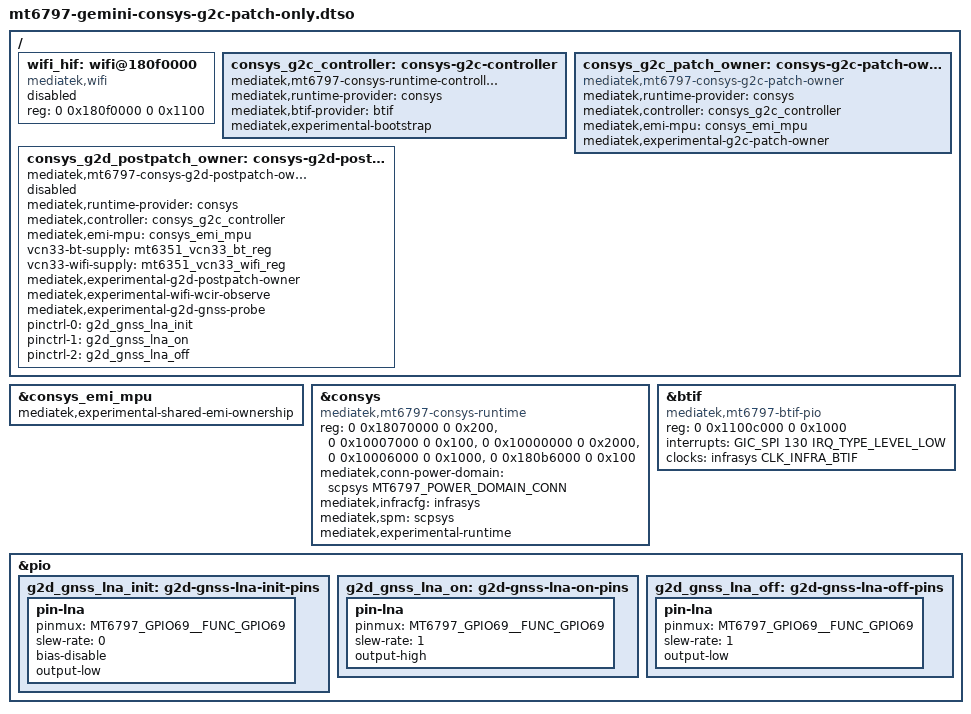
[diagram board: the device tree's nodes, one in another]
// SPDX-License-Identifier: GPL-2.0-only
/*
 * One MT6797 G2c wire-cycle: the G2b chronology plus the hash-pinned WMT
 * patch manifest.  It does not issue WMT function control, register HCI or
 * Wi-Fi, expose a user endpoint, associate, or transmit a host-originated
 * radio frame.  Like G2b, it fences BTIF and restores reset-held state before
 * returning.  Firmware-internal reset effects remain unknown.
 */

/dts-v1/;
/plugin/;

#include <dt-bindings/clock/mt6797-clk.h>
#include <dt-bindings/interrupt-controller/arm-gic.h>
#include <dt-bindings/interrupt-controller/irq.h>
#include <dt-bindings/pinctrl/mt6797-pinfunc.h>
#include <dt-bindings/power/mt6797-power.h>

/ {
	fragment@0 {
		target = <&consys_emi_mpu>;

		__overlay__ {
			mediatek,experimental-shared-emi-ownership;
			status = "okay";
		};
	};

	fragment@1 {
		target = <&consys>;
		#address-cells = <2>;
		#size-cells = <2>;

		__overlay__ {
			compatible = "mediatek,mt6797-consys-runtime";
			reg = <0 0x18070000 0 0x200>,
			      <0 0x10007000 0 0x100>,
			      <0 0x10000000 0 0x2000>,
			      <0 0x10006000 0 0x1000>,
			      <0 0x180b6000 0 0x100>;
			reg-names = "mcu", "ap-rgu", "topckgen", "spm", "afe";
			mediatek,conn-power-domain = <&scpsys MT6797_POWER_DOMAIN_CONN>;
			mediatek,infracfg = <&infrasys>;
			mediatek,spm = <&scpsys>;
			mediatek,experimental-runtime;
			status = "okay";
		};
	};

	fragment@2 {
		target = <&btif>;
		#address-cells = <2>;
		#size-cells = <2>;
		interrupt-parent = <&sysirq>;

		__overlay__ {
			compatible = "mediatek,mt6797-btif-pio";
			reg = <0 0x1100c000 0 0x1000>;
			interrupts = <GIC_SPI 130 IRQ_TYPE_LEVEL_LOW>;
			clocks = <&infrasys CLK_INFRA_BTIF>;
			clock-names = "btifc";
			/delete-property/ reg-shift;
			/delete-property/ reg-io-width;
			status = "okay";
		};
	};

	fragment@3 {
		target-path = "/";

		__overlay__ {
			/*
			 * Vendor mt6797.dtsi:3775-3781 describes the integrated
			 * WLAN SDIO-like AHB portal.  Keep it disabled unless the
			 * isolated W0 profile explicitly selects the observer.
			 */
			wifi_hif: wifi@180f0000 {
				compatible = "mediatek,wifi";
				reg = <0 0x180f0000 0 0x1100>;
				status = "disabled";
			};

			consys_g2c_controller: consys-g2c-controller {
				compatible = "mediatek,mt6797-consys-runtime-controller";
				mediatek,runtime-provider = <&consys>;
				mediatek,btif-provider = <&btif>;
				mediatek,experimental-bootstrap;
				status = "okay";
			};

			consys_g2c_patch_owner: consys-g2c-patch-owner {
				compatible = "mediatek,mt6797-consys-g2c-patch-owner";
				mediatek,runtime-provider = <&consys>;
				mediatek,controller = <&consys_g2c_controller>;
				mediatek,emi-mpu = <&consys_emi_mpu>;
				mediatek,experimental-g2c-patch-owner;
				status = "okay";
			};

			/* G2d is a separately selected successor; never bind it by default. */
			consys_g2d_postpatch_owner: consys-g2d-postpatch-owner {
				compatible = "mediatek,mt6797-consys-g2d-postpatch-owner";
				mediatek,runtime-provider = <&consys>;
				mediatek,controller = <&consys_g2c_controller>;
				mediatek,emi-mpu = <&consys_emi_mpu>;
				vcn33-bt-supply = <&mt6351_vcn33_bt_reg>;
				vcn33-wifi-supply = <&mt6351_vcn33_wifi_reg>;
				mediatek,experimental-g2d-postpatch-owner;
				/* A third DT + command-line gate controls the W0 observation. */
				mediatek,experimental-wifi-wcir-observe;
				/* A second DT + command-line gate controls this GNSS probe. */
				mediatek,experimental-g2d-gnss-probe;
				pinctrl-names = "gps-lna-init", "gps-lna-on", "gps-lna-off";
				pinctrl-0 = <&g2d_gnss_lna_init>;
				pinctrl-1 = <&g2d_gnss_lna_on>;
				pinctrl-2 = <&g2d_gnss_lna_off>;
				status = "disabled";
			};
		};
	};

	/*
	 * Vendor aeon6797_6m_n.dts:1275-1310 assigns host GNSS LNA to GPIO69.
		 * MT6797 needs no GPS_SYNC (wmt_ic_soc.c:1508-1521), so deliberately model
		 * only the observed LNA states. Generic pinconf carries every evidenced
		 * electrical property here.
	 */
	fragment@4 {
		target = <&pio>;

		__overlay__ {
			g2d_gnss_lna_init: g2d-gnss-lna-init-pins {
				pin-lna {
					pinmux = <MT6797_GPIO69__FUNC_GPIO69>;
					slew-rate = <0>;
					bias-disable;
					output-low;
				};
			};

			g2d_gnss_lna_on: g2d-gnss-lna-on-pins {
				pin-lna {
					pinmux = <MT6797_GPIO69__FUNC_GPIO69>;
					slew-rate = <1>;
					output-high;
				};
			};

			g2d_gnss_lna_off: g2d-gnss-lna-off-pins {
				pin-lna {
					pinmux = <MT6797_GPIO69__FUNC_GPIO69>;
					slew-rate = <1>;
					output-low;
				};
			};
		};
	};
};
